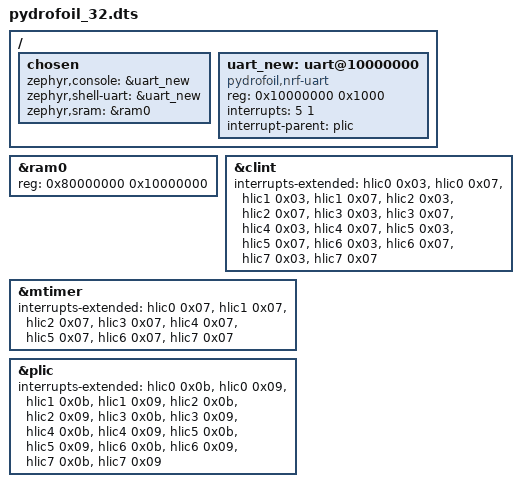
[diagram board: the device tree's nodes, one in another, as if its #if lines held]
/* SPDX-License-Identifier: Apache-2.0 */

/dts-v1/;

#include "virt-riscv32.dtsi"

/ {
	chosen {
		zephyr,console = &uart_new;
		zephyr,shell-uart = &uart_new;
		zephyr,sram = &ram0;
	};
	
	uart_new: uart@10000000 {
		compatible = "pydrofoil,nrf-uart";
		reg = <0x10000000 0x1000>;
		interrupts = <5 1>; /* IRQ_UART0 (system.h:45) */
		interrupt-parent = <&plic>;
		status = "okay";
	};
};

/* 256 MB, genug für IS bis Klasse A (~66 MB). Für mehr (Klasse B braucht
 * ~264 MB) drei Stellen gemeinsam ändern: dieses reg, system.ram in der
 * VP-Config (vcml-pydrofoil/benchmark/zephyr_is/zephyr_is.cfg) und
 * system.core<i>.htif_tohost, das dann im RAM läge (z. B. 0x7FFF0000).
 */
&ram0 {
	reg = <0x80000000 0x10000000>;
};

/* Dynamisches Interrupt-Wiring für CLINT */
&clint {
	status = "okay";
	interrupts-extended = <&hlic0 0x03 &hlic0 0x07>
#if NRCPU > 1
			    , <&hlic1 0x03 &hlic1 0x07>
#endif
#if NRCPU > 2
			    , <&hlic2 0x03 &hlic2 0x07>, <&hlic3 0x03 &hlic3 0x07>
#endif
#if NRCPU > 4
			    , <&hlic4 0x03 &hlic4 0x07>, <&hlic5 0x03 &hlic5 0x07>
			    , <&hlic6 0x03 &hlic6 0x07>, <&hlic7 0x03 &hlic7 0x07>
#endif
			    ;
};

/* Dynamisches Interrupt-Wiring für MTIMER */
&mtimer {
	status = "okay";
	interrupts-extended = <&hlic0 0x07>
#if NRCPU > 1
			    , <&hlic1 0x07>
#endif
#if NRCPU > 2
			    , <&hlic2 0x07>, <&hlic3 0x07>
#endif
#if NRCPU > 4
			    , <&hlic4 0x07>, <&hlic5 0x07>
			    , <&hlic6 0x07>, <&hlic7 0x07>
#endif
			    ;
};

/* Dynamisches Interrupt-Wiring für PLIC
 * Zwei Kontexte pro Hart, wie im VP verdrahtet: Kontext 2i = M-Mode (0x0b),
 * Kontext 2i+1 = S-Mode (0x09). Zephyr nutzt nur die M-Mode-Kontexte.
 */
&plic {
	status = "okay";
	interrupts-extended = <&hlic0 0x0b &hlic0 0x09>
#if NRCPU > 1
			    , <&hlic1 0x0b &hlic1 0x09>
#endif
#if NRCPU > 2
			    , <&hlic2 0x0b &hlic2 0x09>, <&hlic3 0x0b &hlic3 0x09>
#endif
#if NRCPU > 4
			    , <&hlic4 0x0b &hlic4 0x09>, <&hlic5 0x0b &hlic5 0x09>
			    , <&hlic6 0x0b &hlic6 0x09>, <&hlic7 0x0b &hlic7 0x09>
#endif
			    ;
};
